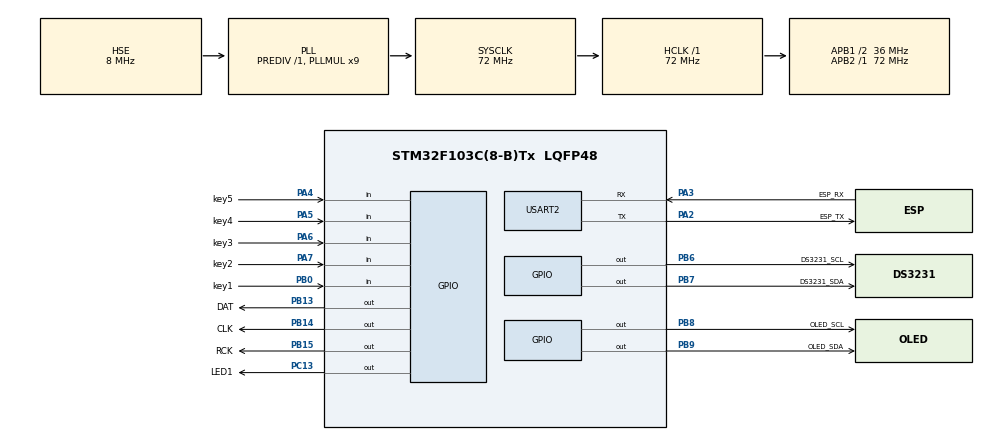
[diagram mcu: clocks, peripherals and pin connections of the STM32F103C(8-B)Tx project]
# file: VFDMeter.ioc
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Mcu.Family=STM32F1
Mcu.Name=STM32F103C(8-B)Tx
Mcu.Package=LQFP48
NVIC.PriorityGroup=NVIC_PRIORITYGROUP_4
NVIC.TIM1_UP_IRQn=true\:0\:0\:false\:false\:true\:true
NVIC.USART2_IRQn=true\:0\:0\:false\:false\:true\:true
PA2.GPIO_Label=ESP_TX
PA2.Mode=Asynchronous
PA2.Signal=USART2_TX
PA3.GPIO_Label=ESP_RX
PA3.Mode=Asynchronous
PA3.Signal=USART2_RX
PA4.GPIO_Label=key5
PA4.GPIO_Mode=GPIO_MODE_INPUT
PA4.GPIO_PuPd=GPIO_PULLUP
PA4.Signal=GPIO_Input
PA5.GPIO_Label=key4
PA5.GPIO_Mode=GPIO_MODE_INPUT
PA5.GPIO_PuPd=GPIO_PULLUP
PA5.Signal=GPIO_Input
PA6.GPIO_Label=key3
PA6.GPIO_Mode=GPIO_MODE_INPUT
PA6.GPIO_PuPd=GPIO_PULLUP
PA6.Signal=GPIO_Input
PA7.GPIO_Label=key2
PA7.GPIO_Mode=GPIO_MODE_INPUT
PA7.GPIO_PuPd=GPIO_PULLUP
PA7.Signal=GPIO_Input
PB0.GPIO_Label=key1
PB0.GPIO_Mode=GPIO_MODE_INPUT
PB0.GPIO_PuPd=GPIO_PULLUP
PB0.Signal=GPIO_Input
PB13.GPIO_Label=DAT
PB13.GPIO_ModeDefaultOutputPP=GPIO_MODE_OUTPUT_PP
PB13.GPIO_PuPd=GPIO_NOPULL
PB13.GPIO_Speed=GPIO_SPEED_FREQ_HIGH
PB13.PinState=GPIO_PIN_SET
PB13.Signal=GPIO_Output
PB14.GPIO_Label=CLK
PB14.GPIO_ModeDefaultOutputPP=GPIO_MODE_OUTPUT_PP
PB14.GPIO_PuPd=GPIO_NOPULL
PB14.GPIO_Speed=GPIO_SPEED_FREQ_HIGH
PB14.PinState=GPIO_PIN_SET
PB14.Signal=GPIO_Output
PB15.GPIO_Label=RCK
PB15.GPIO_ModeDefaultOutputPP=GPIO_MODE_OUTPUT_PP
PB15.GPIO_PuPd=GPIO_NOPULL
PB15.GPIO_Speed=GPIO_SPEED_FREQ_HIGH
PB15.PinState=GPIO_PIN_SET
PB15.Signal=GPIO_Output
PB6.GPIO_Label=DS3231_SCL
PB6.PinState=GPIO_PIN_SET
PB6.Signal=GPIO_Output
PB7.GPIO_Label=DS3231_SDA
PB7.PinState=GPIO_PIN_SET
PB7.Signal=GPIO_Output
PB8.GPIO_Label=OLED_SCL
PB8.PinState=GPIO_PIN_SET
PB8.Signal=GPIO_Output
PB9.GPIO_Label=OLED_SDA
PB9.PinState=GPIO_PIN_SET
PB9.Signal=GPIO_Output
PC13-TAMPER-RTC.GPIO_Label=LED1
PC13-TAMPER-RTC.GPIO_ModeDefaultOutputPP=GPIO_MODE_OUTPUT_PP
PC13-TAMPER-RTC.GPIO_PuPd=GPIO_NOPULL
PC13-TAMPER-RTC.GPIO_Speed=GPIO_SPEED_FREQ_HIGH
PC13-TAMPER-RTC.PinState=GPIO_PIN_SET
PC13-TAMPER-RTC.Signal=GPIO_Output
PD0-OSC_IN.Mode=HSE-External-Oscillator
PD0-OSC_IN.Signal=RCC_OSC_IN
PD1-OSC_OUT.Mode=HSE-External-Oscillator
PD1-OSC_OUT.Signal=RCC_OSC_OUT
ProjectManager.HeapSize=0x200
ProjectManager.StackSize=0x400
ProjectManager.TargetToolchain=MDK-ARM V5
RCC.AHBFreq_Value=72000000
RCC.APB1CLKDivider=RCC_HCLK_DIV2
RCC.APB1Freq_Value=36000000
RCC.APB1TimFreq_Value=72000000
RCC.APB2Freq_Value=72000000
RCC.APB2TimFreq_Value=72000000
RCC.HCLKFreq_Value=72000000
RCC.PLLMUL=RCC_PLL_MUL9
RCC.PLLSourceVirtual=RCC_PLLSOURCE_HSE
RCC.SYSCLKFreq_VALUE=72000000
RCC.SYSCLKSource=RCC_SYSCLKSOURCE_PLLCLK
RCC.USBFreq_Value=72000000
TIM1.Period=1000-1
TIM1.Prescaler=72-2
USART2.VirtualMode=VM_ASYNC
VP_SYS_VS_ND.Mode=No_Debug
VP_TIM1_VS_ClockSourceINT.Mode=Internal
board=custom

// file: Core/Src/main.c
/**
  ******************************************************************************
  * @file           : main.c
  * @brief          : Main program body
  ******************************************************************************
  ** This notice applies to any and all portions of this file
  * that are not between comment pairs USER CODE BEGIN and
  * USER CODE END. Other portions of this file, whether
  * inserted by the user or by software development tools
  * are owned by their respective copyright owners.
  *
  * COPYRIGHT(c) 2019 STMicroelectronics
  *
  * Redistribution and use in source and binary forms, with or without modification,
  * are permitted provided that the following conditions are met:
  *   1. Redistributions of source code must retain the above copyright notice,
  *      this list of conditions and the following disclaimer.
  *   2. Redistributions in binary form must reproduce the above copyright notice,
  *      this list of conditions and the following disclaimer in the documentation
  *      and/or other materials provided with the distribution.
  *   3. Neither the name of STMicroelectronics nor the names of its contributors
  *      may be used to endorse or promote products derived from this software
  *      without specific prior written permission.
  *
  * THIS SOFTWARE IS PROVIDED BY THE COPYRIGHT HOLDERS AND CONTRIBUTORS "AS IS"
  * AND ANY EXPRESS OR IMPLIED WARRANTIES, INCLUDING, BUT NOT LIMITED TO, THE
  * IMPLIED WARRANTIES OF MERCHANTABILITY AND FITNESS FOR A PARTICULAR PURPOSE ARE
  * DISCLAIMED. IN NO EVENT SHALL THE COPYRIGHT HOLDER OR CONTRIBUTORS BE LIABLE
  * FOR ANY DIRECT, INDIRECT, INCIDENTAL, SPECIAL, EXEMPLARY, OR CONSEQUENTIAL
  * DAMAGES (INCLUDING, BUT NOT LIMITED TO, PROCUREMENT OF SUBSTITUTE GOODS OR
  * SERVICES; LOSS OF USE, DATA, OR PROFITS; OR BUSINESS INTERRUPTION) HOWEVER
  * CAUSED AND ON ANY THEORY OF LIABILITY, WHETHER IN CONTRACT, STRICT LIABILITY,
  * OR TORT (INCLUDING NEGLIGENCE OR OTHERWISE) ARISING IN ANY WAY OUT OF THE USE
  * OF THIS SOFTWARE, EVEN IF ADVISED OF THE POSSIBILITY OF SUCH DAMAGE.
  *
  ******************************************************************************
  */
#include "main.h"
#include "stm32f1xx_hal.h"
#include "tim.h"
#include "usart.h"
#include "gpio.h"

/* USER CODE BEGIN Includes */
#include "VFDMain.h"
/* USER CODE END Includes */

/* USER CODE BEGIN PV */
/* Private variables ---------------------------------------------------------*/

/* USER CODE END PV */

void SystemClock_Config(void);

/* USER CODE BEGIN PFP */
/* Private function prototypes -----------------------------------------------*/

/* USER CODE END PFP */

int main(void)
{

  /* MCU Configuration----------------------------------------------------------*/

  /* Reset of all peripherals, Initializes the Flash interface and the Systick. */
  HAL_Init();

  /* Configure the system clock */
  SystemClock_Config();

  /* Initialize all configured peripherals */
  MX_GPIO_Init();
  MX_TIM1_Init();
  MX_USART2_UART_Init();
  /* USER CODE BEGIN 2 */
	VFDMainSetup();
  /* USER CODE END 2 */

  /* Infinite loop */
  while (1)
  {

  /* USER CODE BEGIN 3 */
	VFDMainLoop();
  }
  /* USER CODE END 3 */

}

void SystemClock_Config(void)
{

  RCC_OscInitTypeDef RCC_OscInitStruct;
  RCC_ClkInitTypeDef RCC_ClkInitStruct;

    /**Initializes the CPU, AHB and APB busses clocks
    */
  RCC_OscInitStruct.OscillatorType = RCC_OSCILLATORTYPE_HSE;
  RCC_OscInitStruct.HSEState = RCC_HSE_ON;
  RCC_OscInitStruct.HSEPredivValue = RCC_HSE_PREDIV_DIV1;
  RCC_OscInitStruct.HSIState = RCC_HSI_ON;
  RCC_OscInitStruct.PLL.PLLState = RCC_PLL_ON;
  RCC_OscInitStruct.PLL.PLLSource = RCC_PLLSOURCE_HSE;
  RCC_OscInitStruct.PLL.PLLMUL = RCC_PLL_MUL9;
  if (HAL_RCC_OscConfig(&RCC_OscInitStruct) != HAL_OK)
  {
    _Error_Handler(__FILE__, __LINE__);
  }

    /**Initializes the CPU, AHB and APB busses clocks
    */
  RCC_ClkInitStruct.ClockType = RCC_CLOCKTYPE_HCLK|RCC_CLOCKTYPE_SYSCLK
                              |RCC_CLOCKTYPE_PCLK1|RCC_CLOCKTYPE_PCLK2;
  RCC_ClkInitStruct.SYSCLKSource = RCC_SYSCLKSOURCE_PLLCLK;
  RCC_ClkInitStruct.AHBCLKDivider = RCC_SYSCLK_DIV1;
  RCC_ClkInitStruct.APB1CLKDivider = RCC_HCLK_DIV2;
  RCC_ClkInitStruct.APB2CLKDivider = RCC_HCLK_DIV1;

  if (HAL_RCC_ClockConfig(&RCC_ClkInitStruct, FLASH_LATENCY_2) != HAL_OK)
  {
    _Error_Handler(__FILE__, __LINE__);
  }

    /**Configure the Systick interrupt time
    */
  HAL_SYSTICK_Config(HAL_RCC_GetHCLKFreq()/1000);

    /**Configure the Systick
    */
  HAL_SYSTICK_CLKSourceConfig(SYSTICK_CLKSOURCE_HCLK);

  /* SysTick_IRQn interrupt configuration */
  HAL_NVIC_SetPriority(SysTick_IRQn, 0, 0);
}

void _Error_Handler(char *file, int line)
{
  while(1)
  {
  }
}

/************************ (C) COPYRIGHT STMicroelectronics *****END OF FILE****/
